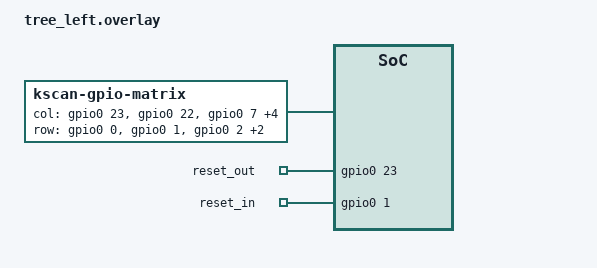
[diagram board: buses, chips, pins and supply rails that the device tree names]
/*
 * Copyright (c) 2022 The ZMK Contributors
 *
 * SPDX-License-Identifier: MIT
 */

/ {
	chosen {
		zmk,kscan = &kscan0;
	};

	kscan0: kscan {
		compatible = "zmk,kscan-gpio-matrix";
    wakeup-source;
		label = "KSCAN";
    diode-direction = "col2row";
		col-gpios
			= <&gpio0 23 (GPIO_ACTIVE_HIGH)>
			, <&gpio0 22 (GPIO_ACTIVE_HIGH)>
			, <&gpio0 7 (GPIO_ACTIVE_HIGH)>
			, <&gpio0 8 (GPIO_ACTIVE_HIGH)>
			, <&gpio0 9 (GPIO_ACTIVE_HIGH)>
			, <&gpio0 10 (GPIO_ACTIVE_HIGH)>
			, <&gpio0 11 (GPIO_ACTIVE_HIGH)>
			;
		row-gpios
			= <&gpio0 0 (GPIO_ACTIVE_HIGH | GPIO_PULL_DOWN)>
			, <&gpio0 1 (GPIO_ACTIVE_HIGH | GPIO_PULL_DOWN)>
			, <&gpio0 2 (GPIO_ACTIVE_HIGH | GPIO_PULL_DOWN)>
			, <&gpio0 3 (GPIO_ACTIVE_HIGH | GPIO_PULL_DOWN)>
			, <&gpio0 4 (GPIO_ACTIVE_HIGH | GPIO_PULL_DOWN)>
			;
	};

	leds {
		resetout: reset_out {
			gpios = <&gpio0 23 (GPIO_ACTIVE_HIGH)>;
			label = "reset_out";
		};
		resetin: reset_in {
			gpios = <&gpio0 1 (GPIO_ACTIVE_HIGH | GPIO_PULL_DOWN)>;
			label = "reset_in";
		};
	};
};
